# ATA5781 device description
Architecture: AVR8; Family: megaAVR
Registers are 8-bit, access not given, no defined reset value unless marked. A register's access mark holds for its fields unless they carry their own. Offsets are from the block's base; [hi:lo] are bit positions; {n}, {i} and the like mark numbered series.

## FE
Instances: FE 0x00
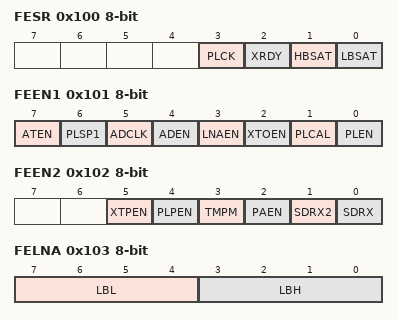
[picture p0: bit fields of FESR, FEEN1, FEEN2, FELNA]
0x100 FESR — Front-End Status Register
  [3] PLCK — PLL locked
  [2] XRDY — XTO ready
  [1] HBSAT — LNA High band saturated
  [0] LBSAT — LNA Low band saturated
0x101 FEEN1 — Front-End Enable Register 1
  [7] ATEN — Antenna Tuning Enable
  [6] PLSP1 — PLL Speedup 1
  [5] ADCLK — ADC Clock enable
  [4] ADEN — Analog Digital Converter enable
  [3] LNAEN — Low Noise Amplifier enable
  [2] XTOEN — Cristal Oscillator enable
  [1] PLCAL — PLL calibration mode
  [0] PLEN — PLL enable
0x102 FEEN2 — Front-End Enable Register 2
  [5] XTPEN — XTO VPump enable
  [4] PLPEN — PLL Post En IQ divider
  [3] TMPM — Temperature measurement
  [2] PAEN — Power Amplifier enable
  [1] SDRX2 — Single Pole Double Throw (SPDT) Switch TX
  [0] SDRX — Single Pole Double Throw (SPDT) Switch RX
0x103 FELNA — Front-End LNA Bias Register
  [7:4] LBL — LNA Bias Low band
  [3:0] LBH — LNA Bias High band
0x106 FEVCT — Front-End VCO Tuning Register
  [3:0] FEVCT
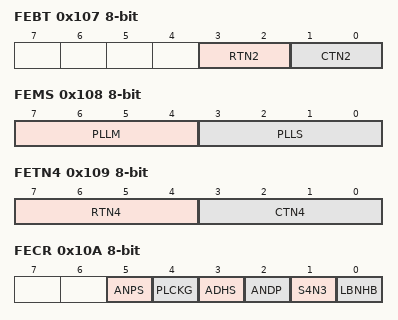
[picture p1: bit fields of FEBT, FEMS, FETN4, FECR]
0x107 FEBT — Front-End RC Tuning Register
  [3:2] RTN2 — Resistor Tuning
  [1:0] CTN2 — Capacitor Tuning
0x108 FEMS — Front-End Main and Swallow Control Register
  [7:4] PLLM — PLL Mode
  [3:0] PLLS — PLL Swallow
0x109 FETN4 — Front-End RC Tuning 4bit Register
  [7:4] RTN4 — 4 bit Resistor Tuning
  [3:0] CTN4 — 4 bit Capacitor Tuning
0x10A FECR — Front-End Control Register
  [5] ANPS — ASK Not DPSK Switch
  [4] PLCKG — PLL Lock Detect Gate
  [3] ADHS — ADC High Sample Rate
  [2] ANDP — Antenna Damping
  [1] S4N3 — Select 433 Not 315MHz Band
  [0] LBNHB — Select Low-Band Not High-Band
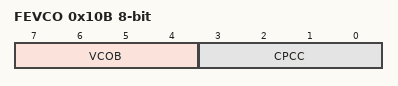
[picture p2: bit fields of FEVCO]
0x10B FEVCO — Front-End VCO and PLL control
  [7:4] VCOB — VCO Bias
  [3:0] CPCC — Charge pump current control
0x10C FEALR — Front-End Antenna Level Detector Range
  [1:0] RNGE — Range of the ANT_TUNE level detector
    0=0..3 dBm; 1=4..7 dBm; 2=8..14 dBm; 3=Secure Measurement
0x10D FEANT — Front-End ANTenna
  [3:0] LVLC — antenna signal LeVeL
0x10E FEBIA — Front-End IF Amplifier BIAS
  [7] IFAEN — IF Amplifier Enable

## FREQS
Instances: FREQS 0x00
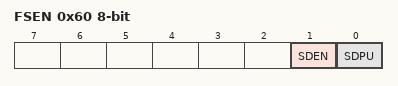
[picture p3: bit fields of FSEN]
0x60 FSEN — Frequency Synthesizer Enable register
  [1] SDEN — Sigma-delta Modulator Enable
  [0] SDPU — Sigma-delta Modulator Power Up
0x64 FFREQ1L — Fractional Frequency 1 Setting, Low Byte
0x65 FFREQ1M — Fractional Frequency 1 Setting, Middle Byte
0x66 FFREQ1H bits used 1:0 — Fractional Frequency 1 Setting, High Byte
0x67 FFREQ2L — Fractional Frequency 2 Setting, Low Byte
0x68 FFREQ2M — Fractional Frequency 2 Setting, Middle Byte
0x69 FFREQ2H bits used 1:0 — Fractional Frequency 2 Setting, High Byte

## FRSYNC
Instances: FRSYNC 0x00
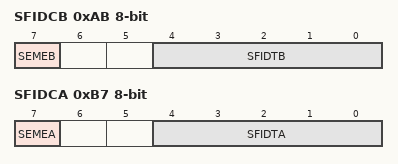
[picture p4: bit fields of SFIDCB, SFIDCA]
0xAB SFIDCB — Start-Frame ID Control for data path B
  [7] SEMEB — Serial mode enable for data path B
  [4:0] SFIDTB — Start-Frame ID threshold for data path B
0xAC SFIDLB — Start-Frame ID Length for data path B
  [5:0] SFIDLB
0xAD WUPTB — Wake-Up Pattern Threshold for data path B
  [4:0] WUPTB
0xAE WUPLB — Wake-Up Pattern Length for data path B
  [5:0] WUPLB
{0xAE+i} SFID{i}B (i=1..4) — Start-Frame ID byte {i} for data path B
{0xB2+i} WUP{i}B (i=1..4) — Wake-Up Pattern byte {i} for data path B
0xB7 SFIDCA — Start-Frame ID Control for data path A
  [7] SEMEA — Serial mode enable for data path A
  [4:0] SFIDTA — Start-Frame ID threshold for data path A
0xB8 SFIDLA — Start-Frame ID Length for data path A
  [5:0] SFIDLA
0xB9 WUPTA — Wake-Up Pattern Threshold for data path A
  [4:0] WUPTA
0xBA WUPLA — Wake-Up Pattern Length for data path A
  [5:0] WUPLA
{0xBA+i} SFID{i}A (i=1..4) — Start-Frame ID byte {i} for data path A
{0xBE+i} WUP{i}A (i=1..4) — Wake-Up Pattern byte {i} for data path A

## GPIOREGS
Instances: GPIOREGS 0x00
0x3A GPIOR0 — General Purpose I/O Register 0
{0x38+i} GPIOR{i} (i=3..6) — General Purpose I/O Register {i}
0x44 GPIOR1 — General Purpose I/O Register 1
0x45 GPIOR2 — General Purpose I/O Register 2
